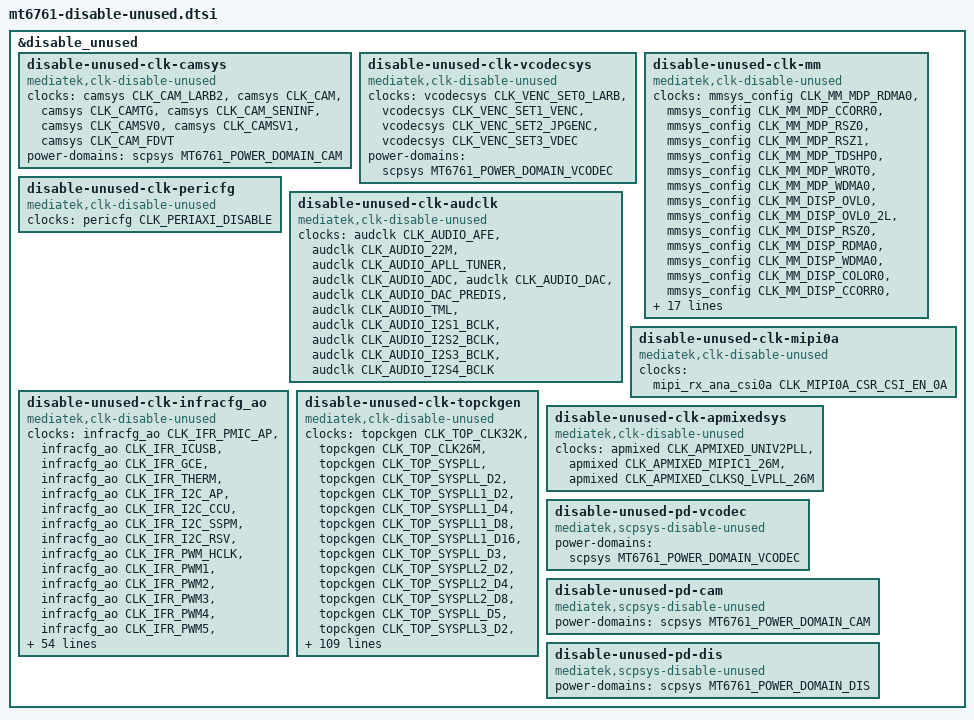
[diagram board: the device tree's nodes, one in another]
// SPDX-License-Identifier: (GPL-2.0 OR MIT)
/*
 * Copyright (C) 2021 MediaTek Inc.
 * Author: Owen Chen <owen.chen@mediatek.com>
 */

&disable_unused {
	status = "okay";
	disable-unused-clk-camsys {
		compatible = "mediatek,clk-disable-unused";
		clocks =
			<&camsys CLK_CAM_LARB2>,
			<&camsys CLK_CAM>,
			<&camsys CLK_CAMTG>,
			<&camsys CLK_CAM_SENINF>,
			<&camsys CLK_CAMSV0>,
			<&camsys CLK_CAMSV1>,
			<&camsys CLK_CAM_FDVT>;
		power-domains = <&scpsys MT6761_POWER_DOMAIN_CAM>;
	};

	disable-unused-clk-vcodecsys {
		compatible = "mediatek,clk-disable-unused";
		clocks =
			<&vcodecsys CLK_VENC_SET0_LARB>,
			<&vcodecsys CLK_VENC_SET1_VENC>,
			<&vcodecsys CLK_VENC_SET2_JPGENC>,
			<&vcodecsys CLK_VENC_SET3_VDEC>;
		power-domains = <&scpsys MT6761_POWER_DOMAIN_VCODEC>;
	};

	disable-unused-clk-mm {
		compatible = "mediatek,clk-disable-unused";
		clocks =
			<&mmsys_config CLK_MM_MDP_RDMA0>,
			<&mmsys_config CLK_MM_MDP_CCORR0>,
			<&mmsys_config CLK_MM_MDP_RSZ0>,
			<&mmsys_config CLK_MM_MDP_RSZ1>,
			<&mmsys_config CLK_MM_MDP_TDSHP0>,
			<&mmsys_config CLK_MM_MDP_WROT0>,
			<&mmsys_config CLK_MM_MDP_WDMA0>,
			<&mmsys_config CLK_MM_DISP_OVL0>,
			<&mmsys_config CLK_MM_DISP_OVL0_2L>,
			<&mmsys_config CLK_MM_DISP_RSZ0>,
			<&mmsys_config CLK_MM_DISP_RDMA0>,
			<&mmsys_config CLK_MM_DISP_WDMA0>,
			<&mmsys_config CLK_MM_DISP_COLOR0>,
			<&mmsys_config CLK_MM_DISP_CCORR0>,
			<&mmsys_config CLK_MM_DISP_AAL0>,
			<&mmsys_config CLK_MM_DISP_GAMMA0>,
			<&mmsys_config CLK_MM_DISP_DITHER0>,
			<&mmsys_config CLK_MM_DSI0>,
			<&mmsys_config CLK_MM_FAKE_ENG>,
			<&mmsys_config CLK_MM_SMI_COMMON>,
			<&mmsys_config CLK_MM_SMI_LARB0>,
			<&mmsys_config CLK_MM_SMI_COMM0>,
			<&mmsys_config CLK_MM_SMI_COMM1>,
			<&mmsys_config CLK_MM_CAM_MDP>,
			<&mmsys_config CLK_MM_SMI_IMG>,
			<&mmsys_config CLK_MM_SMI_CAM>,
			<&mmsys_config CLK_MM_IMG_DL_RELAY>,
			<&mmsys_config CLK_MM_IMG_DL_ASYNC_TOP>,
			<&mmsys_config CLK_MM_DIG_DSI>,
			<&mmsys_config CLK_MM_F26M_HRTWT>;
		power-domains = <&scpsys MT6761_POWER_DOMAIN_DIS>;
	};

	disable-unused-clk-pericfg {
		compatible = "mediatek,clk-disable-unused";
		clocks = <&pericfg CLK_PERIAXI_DISABLE>;
	};

	disable-unused-clk-audclk {
		compatible = "mediatek,clk-disable-unused";
		clocks =
			<&audclk CLK_AUDIO_AFE>,
			<&audclk CLK_AUDIO_22M>,
			<&audclk CLK_AUDIO_APLL_TUNER>,
			<&audclk CLK_AUDIO_ADC>,
			<&audclk CLK_AUDIO_DAC>,
			<&audclk CLK_AUDIO_DAC_PREDIS>,
			<&audclk CLK_AUDIO_TML>,
			<&audclk CLK_AUDIO_I2S1_BCLK>,
			<&audclk CLK_AUDIO_I2S2_BCLK>,
			<&audclk CLK_AUDIO_I2S3_BCLK>,
			<&audclk CLK_AUDIO_I2S4_BCLK>;
	};

	disable-unused-clk-mipi0a {
		compatible = "mediatek,clk-disable-unused";
		clocks = <&mipi_rx_ana_csi0a CLK_MIPI0A_CSR_CSI_EN_0A>;
	};

	disable-unused-clk-infracfg_ao {
		compatible = "mediatek,clk-disable-unused";
		clocks =
			<&infracfg_ao CLK_IFR_PMIC_AP>,
			<&infracfg_ao CLK_IFR_ICUSB>,
			<&infracfg_ao CLK_IFR_GCE>,
			<&infracfg_ao CLK_IFR_THERM>,
			<&infracfg_ao CLK_IFR_I2C_AP>,
			<&infracfg_ao CLK_IFR_I2C_CCU>,
			<&infracfg_ao CLK_IFR_I2C_SSPM>,
			<&infracfg_ao CLK_IFR_I2C_RSV>,
			<&infracfg_ao CLK_IFR_PWM_HCLK>,
			<&infracfg_ao CLK_IFR_PWM1>,
			<&infracfg_ao CLK_IFR_PWM2>,
			<&infracfg_ao CLK_IFR_PWM3>,
			<&infracfg_ao CLK_IFR_PWM4>,
			<&infracfg_ao CLK_IFR_PWM5>,
			<&infracfg_ao CLK_IFR_PWM>,
			<&infracfg_ao CLK_IFR_UART0>,
			<&infracfg_ao CLK_IFR_UART1>,
			<&infracfg_ao CLK_IFR_GCE_26M>,
			<&infracfg_ao CLK_IFR_CQ_DMA_FPC>,
			<&infracfg_ao CLK_IFR_BTIF>,
			<&infracfg_ao CLK_IFR_SPI0>,
			<&infracfg_ao CLK_IFR_MSDC0>,
			<&infracfg_ao CLK_IFR_MSDC1>,
			<&infracfg_ao CLK_IFR_TRNG>,
			<&infracfg_ao CLK_IFR_AUXADC>,
			<&infracfg_ao CLK_IFR_CCIF1_AP>,
			<&infracfg_ao CLK_IFR_CCIF1_MD>,
			<&infracfg_ao CLK_IFR_AUXADC_MD>,
			<&infracfg_ao CLK_IFR_AP_DMA>,
			<&infracfg_ao CLK_IFR_DEVICE_APC>,
			<&infracfg_ao CLK_IFR_CCIF_AP>,
			<&infracfg_ao CLK_IFR_AUDIO>,
			<&infracfg_ao CLK_IFR_CCIF_MD>,
			<&infracfg_ao CLK_IFR_RG_PWM_FBCLK6>,
			<&infracfg_ao CLK_IFR_DISP_PWM>,
			<&infracfg_ao CLK_IFR_CLDMA_BCLK>,
			<&infracfg_ao CLK_IFR_AUDIO_26M_BCLK>,
			<&infracfg_ao CLK_IFR_SPI1>,
			<&infracfg_ao CLK_IFR_I2C4>,
			<&infracfg_ao CLK_IFR_SPI2>,
			<&infracfg_ao CLK_IFR_SPI3>,
			<&infracfg_ao CLK_IFR_I2C5>,
			<&infracfg_ao CLK_IFR_I2C5_ARBITER>,
			<&infracfg_ao CLK_IFR_I2C5_IMM>,
			<&infracfg_ao CLK_IFR_I2C1_ARBITER>,
			<&infracfg_ao CLK_IFR_I2C1_IMM>,
			<&infracfg_ao CLK_IFR_I2C2_ARBITER>,
			<&infracfg_ao CLK_IFR_I2C2_IMM>,
			<&infracfg_ao CLK_IFR_SPI4>,
			<&infracfg_ao CLK_IFR_SPI5>,
			<&infracfg_ao CLK_IFR_CQ_DMA>,
			<&infracfg_ao CLK_IFR_BIST2FPC>,
			<&infracfg_ao CLK_IFR_FAES_FDE>,
			<&infracfg_ao CLK_IFR_MSDC0_SELF>,
			<&infracfg_ao CLK_IFR_MSDC1_SELF>,
			<&infracfg_ao CLK_IFR_MSDC2_SELF>,
			<&infracfg_ao CLK_IFR_UFS_AXI>,
			<&infracfg_ao CLK_IFR_I2C6>,
			<&infracfg_ao CLK_IFR_AP_MSDC0>,
			<&infracfg_ao CLK_IFR_MD_MSDC0>,
			<&infracfg_ao CLK_IFR_MSDC0_SRC>,
			<&infracfg_ao CLK_IFR_MSDC1_SRC>,
			<&infracfg_ao CLK_IFR_MSDC2_SRC>,
			<&infracfg_ao CLK_IFR_MCU_PM_BCLK>,
			<&infracfg_ao CLK_IFR_CCIF2_AP>,
			<&infracfg_ao CLK_IFR_CCIF2_MD>,
			<&infracfg_ao CLK_IFR_CCIF3_AP>,
			<&infracfg_ao CLK_IFR_CCIF3_MD>;
	};

	disable-unused-clk-topckgen {
		compatible = "mediatek,clk-disable-unused";
		clocks =
			<&topckgen CLK_TOP_CLK32K>,
			<&topckgen CLK_TOP_CLK26M>,
			<&topckgen CLK_TOP_SYSPLL>,
			<&topckgen CLK_TOP_SYSPLL_D2>,
			<&topckgen CLK_TOP_SYSPLL1_D2>,
			<&topckgen CLK_TOP_SYSPLL1_D4>,
			<&topckgen CLK_TOP_SYSPLL1_D8>,
			<&topckgen CLK_TOP_SYSPLL1_D16>,
			<&topckgen CLK_TOP_SYSPLL_D3>,
			<&topckgen CLK_TOP_SYSPLL2_D2>,
			<&topckgen CLK_TOP_SYSPLL2_D4>,
			<&topckgen CLK_TOP_SYSPLL2_D8>,
			<&topckgen CLK_TOP_SYSPLL_D5>,
			<&topckgen CLK_TOP_SYSPLL3_D2>,
			<&topckgen CLK_TOP_SYSPLL3_D4>,
			<&topckgen CLK_TOP_SYSPLL_D7>,
			<&topckgen CLK_TOP_SYSPLL4_D2>,
			<&topckgen CLK_TOP_SYSPLL4_D4>,
			<&topckgen CLK_TOP_USB20_192M>,
			<&topckgen CLK_TOP_USB20_192M_D4>,
			<&topckgen CLK_TOP_USB20_192M_D8>,
			<&topckgen CLK_TOP_USB20_192M_D16>,
			<&topckgen CLK_TOP_USB20_192M_D32>,
			<&topckgen CLK_TOP_USB_PHY48M>,
			<&topckgen CLK_TOP_UNIVPLL>,
			<&topckgen CLK_TOP_UNIVPLL_D2>,
			<&topckgen CLK_TOP_UNIVPLL1_D2>,
			<&topckgen CLK_TOP_UNIVPLL1_D4>,
			<&topckgen CLK_TOP_UNIVPLL_D3>,
			<&topckgen CLK_TOP_UNIVPLL2_D2>,
			<&topckgen CLK_TOP_UNIVPLL2_D4>,
			<&topckgen CLK_TOP_UNIVPLL2_D8>,
			<&topckgen CLK_TOP_UNIVPLL2_D32>,
			<&topckgen CLK_TOP_UNIVPLL_D5>,
			<&topckgen CLK_TOP_UNIVPLL3_D2>,
			<&topckgen CLK_TOP_UNIVPLL3_D4>,
			<&topckgen CLK_TOP_MMPLL>,
			<&topckgen CLK_TOP_MMPLL_D2>,
			<&topckgen CLK_TOP_MPLL_104M>,
			<&topckgen CLK_TOP_MPLL_52M>,
			<&topckgen CLK_TOP_MFGPLL>,
			<&topckgen CLK_TOP_MSDCPLL>,
			<&topckgen CLK_TOP_MSDCPLL_D2>,
			<&topckgen CLK_TOP_APLL1>,
			<&topckgen CLK_TOP_APLL1_D2>,
			<&topckgen CLK_TOP_APLL1_D4>,
			<&topckgen CLK_TOP_APLL1_D8>,
			<&topckgen CLK_TOP_ULPOSC1_D2>,
			<&topckgen CLK_TOP_ULPOSC1_D4>,
			<&topckgen CLK_TOP_ULPOSC1_D8>,
			<&topckgen CLK_TOP_ULPOSC1_D16>,
			<&topckgen CLK_TOP_ULPOSC1_D32>,
			<&topckgen CLK_TOP_DMPLL>,
			<&topckgen CLK_TOP_DA_USB20_48M_DIV>,
			<&topckgen CLK_TOP_DA_UNIV_48M_DIV>,
			<&topckgen CLK_TOP_DA_MPLL_104M_DIV>,
			<&topckgen CLK_TOP_DA_MPLL_52M_DIV>,
			<&topckgen CLK_TOP_CSW_FAXI>,
			<&topckgen CLK_TOP_CSW_FMSDC30_1>,
			<&topckgen CLK_TOP_CSW_FMSDC30_2>,
			<&topckgen CLK_TOP_AXI>,
			<&topckgen CLK_TOP_MEM>,
			<&topckgen CLK_TOP_MM>,
			<&topckgen CLK_TOP_SCP>,
			<&topckgen CLK_TOP_MFG>,
			<&topckgen CLK_TOP_F_FUART>,
			<&topckgen CLK_TOP_SPI>,
			<&topckgen CLK_TOP_MSDC50_0>,
			<&topckgen CLK_TOP_AUDIO>,
			<&topckgen CLK_TOP_AUD_1>,
			<&topckgen CLK_TOP_AUD_ENGEN1>,
			<&topckgen CLK_TOP_F_FDISP_PWM>,
			<&topckgen CLK_TOP_SSPM>,
			<&topckgen CLK_TOP_DXCC>,
			<&topckgen CLK_TOP_I2C>,
			<&topckgen CLK_TOP_F_FPWM>,
			<&topckgen CLK_TOP_F_FSENINF>,
			<&topckgen CLK_TOP_AES_FDE>,
			<&topckgen CLK_TOP_F_BIST2FPC>,
			<&topckgen CLK_TOP_ARMPLL_DIVIDER_PLL0>,
			<&topckgen CLK_TOP_ARMPLL_DIVIDER_PLL1>,
			<&topckgen CLK_TOP_ARMPLL_DIVIDER_PLL2>,
			<&topckgen CLK_TOP_UFS_TICK1US>,
			<&topckgen CLK_TOP_APLL12_DIV0>,
			<&topckgen CLK_TOP_APLL12_DIV1>,
			<&topckgen CLK_TOP_APLL12_DIV2>,
			<&topckgen CLK_TOP_APLL12_DIV3>,
			<&topckgen CLK_TOP_APLL12_DIV4>,
			<&topckgen CLK_TOP_APLL12_DIVB>,
			<&topckgen CLK_TOP_ARMPLL_DIVIDER_PLL0_EN>,
			<&topckgen CLK_TOP_ARMPLL_DIVIDER_PLL1_EN>,
			<&topckgen CLK_TOP_ARMPLL_DIVIDER_PLL2_EN>,
			<&topckgen CLK_TOP_FMEM_OCC_DRC_EN>,
			<&topckgen CLK_TOP_F_BIST2FPC_EN>,
			<&topckgen CLK_TOP_QS_CG>,
			<&topckgen CLK_TOP_AXI_SEL>,
			<&topckgen CLK_TOP_MEM_SEL>,
			<&topckgen CLK_TOP_MM_SEL>,
			<&topckgen CLK_TOP_SCP_SEL>,
			<&topckgen CLK_TOP_MFG_SEL>,
			<&topckgen CLK_TOP_ATB_SEL>,
			<&topckgen CLK_TOP_CAMTG_SEL>,
			<&topckgen CLK_TOP_CAMTG1_SEL>,
			<&topckgen CLK_TOP_CAMTG2_SEL>,
			<&topckgen CLK_TOP_CAMTG3_SEL>,
			<&topckgen CLK_TOP_UART_SEL>,
			<&topckgen CLK_TOP_SPI_SEL>,
			<&topckgen CLK_TOP_MSDC50_0_HCLK_SEL>,
			<&topckgen CLK_TOP_MSDC50_0_SEL>,
			<&topckgen CLK_TOP_MSDC30_1_SEL>,
			<&topckgen CLK_TOP_AUDIO_SEL>,
			<&topckgen CLK_TOP_AUD_INTBUS_SEL>,
			<&topckgen CLK_TOP_AUD_1_SEL>,
			<&topckgen CLK_TOP_AUD_ENGEN1_SEL>,
			<&topckgen CLK_TOP_DISP_PWM_SEL>,
			<&topckgen CLK_TOP_SSPM_SEL>,
			<&topckgen CLK_TOP_DXCC_SEL>,
			<&topckgen CLK_TOP_USB_TOP_SEL>,
			<&topckgen CLK_TOP_SPM_SEL>,
			<&topckgen CLK_TOP_I2C_SEL>,
			<&topckgen CLK_TOP_PWM_SEL>,
			<&topckgen CLK_TOP_SENINF_SEL>,
			<&topckgen CLK_TOP_AES_FDE_SEL>,
			<&topckgen CLK_TOP_PWRAP_ULPOSC_SEL>,
			<&topckgen CLK_TOP_CAMTM_SEL>,
			<&topckgen CLK_TOP_CLK13M>;
	};

	disable-unused-clk-apmixedsys {
		compatible = "mediatek,clk-disable-unused";
		clocks =
			<&apmixed CLK_APMIXED_UNIV2PLL>,
			<&apmixed CLK_APMIXED_MIPIC1_26M>,
			<&apmixed CLK_APMIXED_CLKSQ_LVPLL_26M>;
	};

	disable-unused-pd-vcodec {
		compatible = "mediatek,scpsys-disable-unused";
		power-domains = <&scpsys MT6761_POWER_DOMAIN_VCODEC>;
	};

	disable-unused-pd-cam {
		compatible = "mediatek,scpsys-disable-unused";
		power-domains = <&scpsys MT6761_POWER_DOMAIN_CAM>;
	};

	disable-unused-pd-dis {
		compatible = "mediatek,scpsys-disable-unused";
		power-domains = <&scpsys MT6761_POWER_DOMAIN_DIS>;
	};
};
